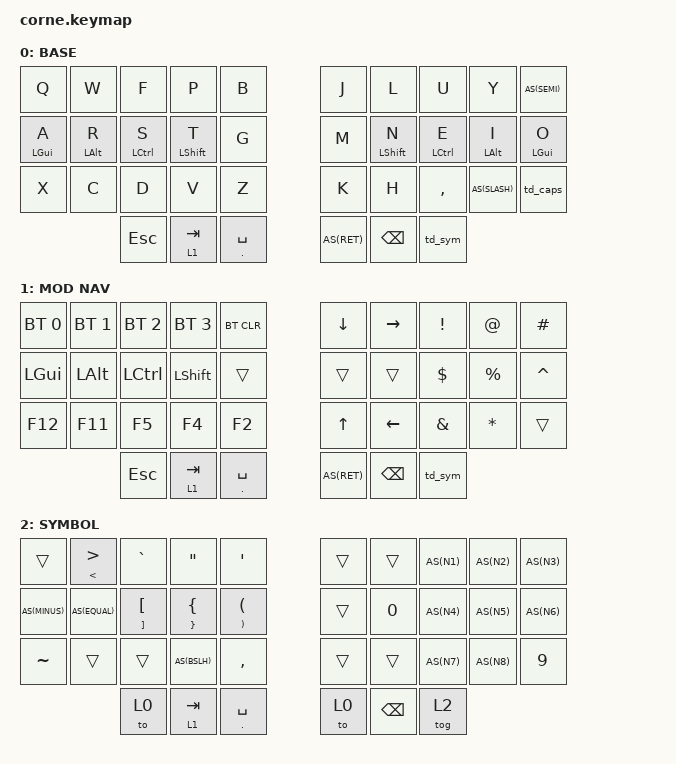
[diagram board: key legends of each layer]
/*
 * Copyright (c) 2020 The ZMK Contributors
 *
 * SPDX-License-Identifier: MIT
 */

#include <behaviors.dtsi>
#include <dt-bindings/zmk/keys.h>
#include <dt-bindings/zmk/bt.h>

#define AS(keycode) &ht LS(keycode) keycode

/ {
    chosen {
        zmk,physical-layout = &foostan_corne_5col_layout;
    };

    behaviors {
      ht: hold_tap {
        compatible = "zmk,behavior-hold-tap";
        #binding-cells = <2>;
        tapping_term_ms = <200>;
        quick_tap_ms = <0>;
        flavor = "tap-preferred";
        bindings = <&kp>, <&kp>;
      };
      td_sym: tap_dance_symbols {
        compatible = "zmk,behavior-tap-dance";
        #binding-cells = <0>;
        tapping-term-ms = <200>;
        bindings = <&sl 2>, <&tog 2>;
      };
      td_caps: tap_dance_capsword {
        compatible = "zmk,behavior-tap-dance";
        #binding-cells = <0>;
        tapping-term-ms = <200>;
        bindings = <&none>, <&caps_word>;
      };
    };
        keymap {
                compatible = "zmk,keymap";

                default_layer {
// -----------------------------------------------------------------------------------------
// |   Q   |   W   |    F   |    P    |  B  |     |  J  |    L    |    U   |   Y   |  SEMI  |
// | A GUI | R ALT | S CTRL | T SHIFT |  G  |     |  M  | N SHIFT | E CTRL | I ALT |  O GUI |
// |   X   |   C   |    D   |    V    |  Z  |     |  K  |    H    |   ,    |  /?   |  CAPS  |
//                 |   ESC  |   TAB   | SPC |     | ENT |  BSPC   |   L2   |
                       display-name = "BASE";
                       bindings = <
   &kp Q      &kp W      &kp F        &kp P        &kp B          &kp J    &kp L         &kp U        &kp Y        AS(SEMI)
   &ht LGUI A &ht LALT R &ht LCTRL S  &ht LSHFT T  &kp G          &kp M    &ht LSHFT N   &ht LCTRL E  &ht LALT I   &ht LGUI O
   &kp X      &kp C      &kp D        &kp V        &kp Z          &kp K    &kp H         &kp COMMA    AS(SLASH)    &td_caps
                         &kp ESC      &lt 1 TAB    &ht DOT SPACE  AS(RET)  &kp BSPC      &td_sym
                       >;
                };

                lower_layer {
// -----------------------------------------------------------------------------------------
// | BT1 | BT2 | BT3  | BT4 | BTCLR |     | DWN | RGT  |  !  |  @  |  #  |
// | GUI | ALT | CTL  | SHF |       |     |     |      |  $  |  %  |  ^  |
// | F12 | F11 | F5   | F4  |  F2   |     | UP  | LFT  |  &  |  *  |     |
//             | ESC  | TAB |  SPC  |     | ENT | BSPC | L2  |
                        display-name = "MOD NAV";
                        bindings = <
   &bt BT_SEL 0  &bt BT_SEL 1  &bt BT_SEL 2  &bt BT_SEL 3 &bt BT_CLR     &kp DOWN  &kp RIGHT  &kp EXCL  &kp AT     &kp HASH
   &kp LGUI      &kp LALT      &kp LCTRL     &kp LSHFT    &trans         &trans    &trans     &kp DLLR  &kp PRCNT  &kp CARET
   &kp F12       &kp F11       &kp F5        &kp F4       &kp F2         &kp UP    &kp LEFT   &kp AMPS  &kp STAR   &trans
                               &kp ESC       &lt 1 TAB    &ht DOT SPACE  AS(RET)   &kp BSPC   &td_sym
                        >;
                };

                raise_layer {
// -----------------------------------------------------------------------------------------
// |    | <> | ``  | ""  | ''  |     |     |    |  1!  | 2@ | 3# |
// | -_ | =+ | []  | {}  | ()  |     |     | 0  |  4$  | 5% | 6^ |
// | ~  |    |     | \|  |  ,  |     |     |    |  7&  | 8* | 9  |
//           | ESC | TAB | SPC |     | ENT | L2 | BSPC |
                        display-name = "SYMBOL";
                        bindings = <
   &trans     &ht LT GT  &kp GRAVE      &kp DQT        &kp SQT        &trans   &trans    AS(N1)  AS(N2)  AS(N3)
   AS(MINUS)  AS(EQUAL)  &ht RBKT LBKT  &ht RBRC LBRC  &ht RPAR LPAR  &trans   &kp N0    AS(N4)  AS(N5)  AS(N6)
   &kp TILDE  &trans     &trans         AS(BSLH)       &kp COMMA      &trans   &trans    AS(N7)  AS(N8)  &kp N9
                         &to 0          &lt 1 TAB      &ht DOT SPACE  &to 0    &kp BSPC  &tog 2
                        >;
                };

                extra_1 {
                        status = "reserved";
                };

                extra_2 {
                        status = "reserved";
                };

                extra_3 {
                        status = "reserved";
                };
        };
};
